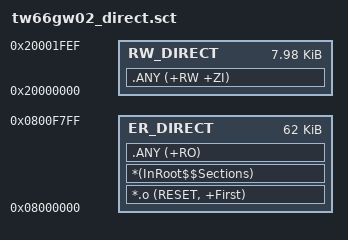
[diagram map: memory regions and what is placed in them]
; Direct-start diagnostic application without the OTA bootloader.
LR_DIRECT 0x08000000 0x0000F800
{
  ER_DIRECT 0x08000000 0x0000F800
  {
    *.o (RESET, +First)
    *(InRoot$$Sections)
    .ANY (+RO)
  }
  RW_DIRECT 0x20000000 0x00001FF0
  {
    .ANY (+RW +ZI)
  }
}
